# SYS_445 register map
Vendor: Texas Instruments
Peripheral module from a debugger description file (folder msp430).
Registers are 16-bit, read-write, no defined reset value unless marked. A register's access mark holds for its fields unless they carry their own. Offsets are as the file gives them; lines under a group give offsets from that group; [hi:lo] are bit positions; {n}, {i} and the like mark numbered series; 'fields as' and 'values as' point back to an identical list; <NAME> marks a mode.

## SYS
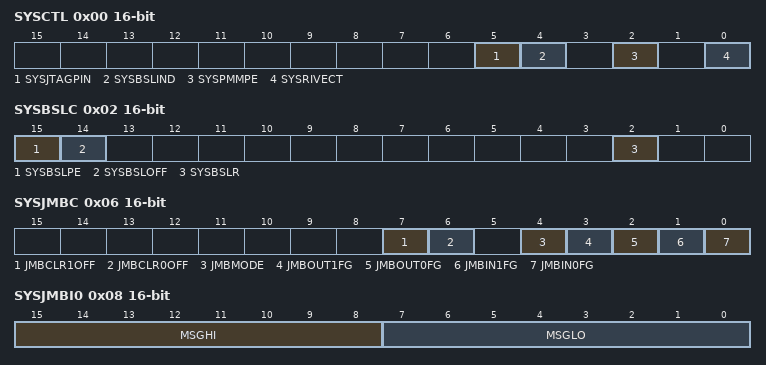
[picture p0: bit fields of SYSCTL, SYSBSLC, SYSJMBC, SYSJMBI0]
0x00 SYSCTL access per field — System Control
  [5] SYSJTAGPIN rw — Dedicated JTAG pins enable
    0=SHARED (Shared JTAG pins (JTAG mode selectable using SBW sequence)); 1=DEDICATED (Dedicated JTAG pins (explicit 4-wire JTAG mode selection))
  [4] SYSBSLIND ro — BSL entry indication
    0=No BSL entry sequence detected; 1=BSL entry sequence detected
  [2] SYSPMMPE rw — PMM access protect
    0=Access from anywhere in memory; 1=Access only from the BSL segments
  [0] SYSRIVECT rw — RAM-based interrupt vectors
    0=FRAM (Interrupt vectors generated with end address TOP of lower 64K FRAM FFFFh); 1=RAM (Interrupt vectors generated with end address TOP of RAM, when RAM available)
0x02 SYSBSLC — Bootstrap Loader Configuration Register
  [15] SYSBSLPE — Bootstrap loader memory protection enable for the size covered in SYSBSLSIZE. By default, this bit is cleared by hardware with a BOR event (as indicated above); however, the boot code that checks for an available BSL may set this bit in software to protect the BSL. Because devices normally come with a TI BSL preprogrammed and protected, the boot code sets this bit.
    0=Area not protected. Read, program, and erase of BSL memory is possible.; 1=Area protected
  [14] SYSBSLOFF — Bootstrap loader memory disable for the size covered in SYSBSLSIZE
    0=BSL memory is addressed when this area is read; 1=BSL memory behaves like vacant memory. Reads cause 3FFFh to be read. Fetches cause JMP $ to be executed.
  [2] SYSBSLR — RAM assigned to BSL
    0=No RAM assigned to BSL area; 1=Lowest 16 bytes of RAM assigned to BSL
0x06 SYSJMBC access per field — JTAG Mailbox Control
  [7] JMBCLR1OFF rw — Incoming JTAG Mailbox 1 flag auto-clear disable
    0=JMBIN1FG cleared on read of JMB1IN register; 1=JMBIN1FG cleared by software
  [6] JMBCLR0OFF rw — Incoming JTAG Mailbox 0 flag auto-clear disable
    0=JMBIN0FG cleared on read of JMB0IN register; 1=JMBIN0FG cleared by software
  [4] JMBMODE rw — Operation mode of JMB
    0=16BIT (16-bit transfers using JMBO0 and JMBI0 only); 1=32BIT (32-bit transfers using JMBO0 with JMBO1 and JMBI0 with JMBI1)
  [3] JMBOUT1FG ro — Outgoing JTAG Mailbox 1 flag
    0=JMBO1 is not ready to receive new data; 1=JMBO1 is ready to receive new data
  [2] JMBOUT0FG ro — Outgoing JTAG Mailbox 0 flag
    0=JMBO0 is not ready to receive new data; 1=JMBO0 is ready to receive new data
  [1] JMBIN1FG rw — Incoming JTAG Mailbox 1 flag
    0=JMBI1 has no new data; 1=JMBI1 has new data available
  [0] JMBIN0FG rw — Incoming JTAG Mailbox 0 flag
    0=JMBI0 has no new data; 1=JMBI0 has new data available
0x08 SYSJMBI0 — JTAG Mailbox Input
  [15:8] MSGHI — JTAG mailbox incoming message high byte
  [7:0] MSGLO — JTAG mailbox incoming message low byte
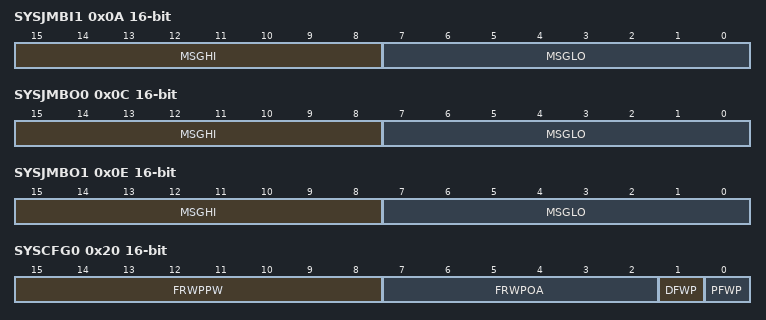
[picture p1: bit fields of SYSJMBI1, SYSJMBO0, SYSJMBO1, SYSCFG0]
0x0A SYSJMBI1 — JTAG Mailbox Input 1 Register
  fields as SYSJMBI0
0x0C SYSJMBO0 — JTAG Mailbox Output
  [15:8] MSGHI — JTAG mailbox outgoing message high byte
  [7:0] MSGLO — JTAG mailbox outgoing message low byte
0x0E SYSJMBO1 — JTAG Mailbox Output 1 Register
  fields as SYSJMBO0
0x1A SYSUNIV ro — User NMI Vector Generator
  [15:0] SYSUNIV — User NMI vector
    0=NONE (No interrupt pending); 2=NMIIFG (NMIIFG NMI pin); 4=OFIFG (OFIFG oscillator fault)
0x1C SYSSNIV ro — System NMI Vector Generator
  [15:0] SYSSNIV — System NMI vector
    0=NONE (No interrupt pending); 2=SVSLIFG (SVS low-power reset entry); 4=UBDIFG (Uncorrectable FRAM bit error detection); 6=ACCTEIFG (FRAM Access Time Error); 18=VMAIFG (VMAIFG Vacant memory access); 20=JMBINIFG (JMBINIFG JTAG mailbox input); 22=JMBOUTIFG (JMBOUTIFG JTAG mailbox output); 24=CBDIFG (Correctable FRAM bit error detection)
0x1E SYSRSTIV ro — Reset Vector Generator
  [15:0] SYSRSTIV — Reset interrupt vector
    0=NONE (No interrupt pending); 2=BOR (Brownout); 4=RSTNMI (RSTIFG RST/NMI); 6=PMMSWBOR (PMMSWBOR software BOR); 8=LPM5WU (LPMx.5 wakeup); 10=SECYV (Security violation); 14=SVSHIFG (SVSHIFG SVSH event); 20=PMMSWPOR (PMMSWPOR software POR); 22=WDTIFG (WDTIFG watchdog timeout); 24=WDTPW (WDTPW watchdog password violation); 26=FRCTLPW (FRCTLPW password violation); 28=UBDIFG (Uncorrectable FRAM bit error detection); 30=PERF (Peripheral area fetch); 32=PMMPW (PMM password violation); 36=FLLUL (FLL unlock (PUC))
0x20 SYSCFG0 — System Configuration Register 0
  [15:8] FRWPPW — FRAM protection password, FRAM protection password. Write with 0A5h to unlock the FRAM protection registers. Always reads as 096h
  [7:2] FRWPOA — Program FRAM write protection offset address from the beginning of Program FRAM. The offset increases by 1KB resolution
  [1] DFWP — Data FRAM write protection
    0=Data FRAM write enable; 1=Data FRAM write protected (not writable)
  [0] PFWP — Program FRAM write protection
    0=Program FRAM write enable; 1=Program FRAM write protected (not writable)
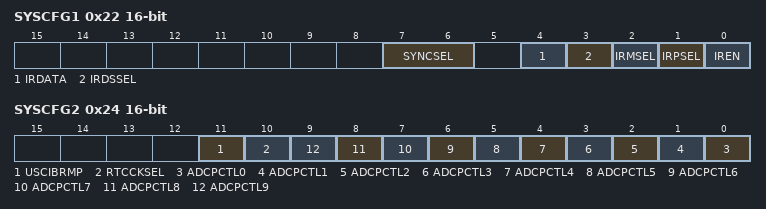
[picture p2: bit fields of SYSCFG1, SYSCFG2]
0x22 SYSCFG1 — System Configuration Register 1
  [7:6] SYNCSEL — Captivate Conversion triggered Source Selection
    0=External source is selected; 1=ADC as the source is selected; 2=internal source is selected
  [4] IRDATA — Infrared data
    0=Infrared data logic 0; 1=Infrared data logic 1
  [3] IRDSSEL — Infrared data source select
    0=From hardware peripherals upon device configuration; 1=From IRDATA bit
  [2] IRMSEL — Infrared mode select
    0=FSK mode; 1=ASK mode
  [1] IRPSEL — Infrared polarity select
    0=Normal polarity; 1=Inverted polarity
  [0] IREN — Infrared enable
    0=Infrared function disabled; 1=Infrared function enabled
0x24 SYSCFG2 — System Configuration Register 2
  [11] USCIBRMP — eUSCIB Remapping source selection , please refer to device specific for details
    0=P1.x is selected, please refer to device specific for details; 1=other port is selected, please refer to device specific for details
  [10] RTCCKSEL — RTC clock selection
    0=RTC_SMCLK (SMCLK is selected); 1=RTC_ACLK (ACLK is selected)
  [n] ADCPCTL{n} (n=0..9) — ADC input A{n} pin select
    0=ADC input A{n} disabled; 1=ADC input A{n} enabled
0x26 SYSCFG3 — System Configuration Register 3
  [0] USCIARMP — eUSCIA remapping source selection, please refer to device specific for details
    values as SYSCFG2.USCIBRMP
